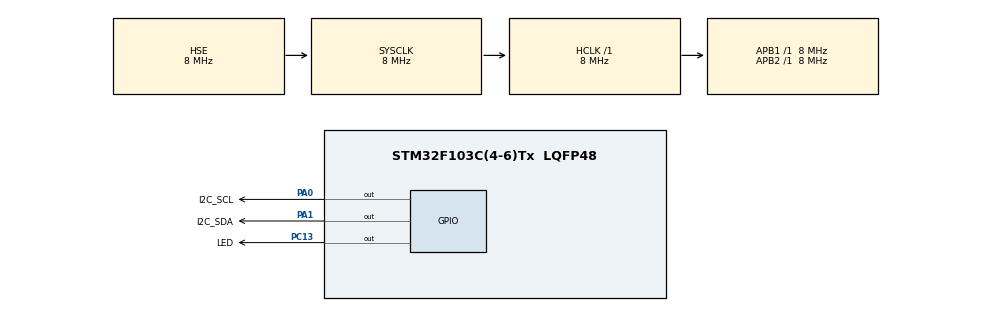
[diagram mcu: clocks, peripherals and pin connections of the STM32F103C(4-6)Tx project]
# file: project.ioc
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Mcu.Family=STM32F1
Mcu.Name=STM32F103C(4-6)Tx
Mcu.Package=LQFP48
NVIC.PriorityGroup=NVIC_PRIORITYGROUP_4
NVIC.TIM3_IRQn=true\:0\:0\:false\:false\:true\:true\:true\:true
PA0-WKUP.GPIO_Label=I2C_SCL
PA0-WKUP.GPIO_ModeDefaultOutputPP=GPIO_MODE_OUTPUT_OD
PA0-WKUP.GPIO_PuPd=GPIO_PULLUP
PA0-WKUP.GPIO_Speed=GPIO_SPEED_FREQ_HIGH
PA0-WKUP.PinState=GPIO_PIN_SET
PA0-WKUP.Signal=GPIO_Output
PA1.GPIO_Label=I2C_SDA
PA1.GPIO_ModeDefaultOutputPP=GPIO_MODE_OUTPUT_OD
PA1.GPIO_PuPd=GPIO_PULLUP
PA1.GPIO_Speed=GPIO_SPEED_FREQ_HIGH
PA1.PinState=GPIO_PIN_SET
PA1.Signal=GPIO_Output
PA13.Mode=Serial_Wire
PA13.Signal=SYS_JTMS-SWDIO
PA14.Mode=Serial_Wire
PA14.Signal=SYS_JTCK-SWCLK
PC13-TAMPER-RTC.GPIO_Label=LED
PC13-TAMPER-RTC.Signal=GPIO_Output
PC14-OSC32_IN.Mode=LSE-External-Oscillator
PC14-OSC32_IN.Signal=RCC_OSC32_IN
PC15-OSC32_OUT.Mode=LSE-External-Oscillator
PC15-OSC32_OUT.Signal=RCC_OSC32_OUT
PD0-OSC_IN.Mode=HSE-External-Oscillator
PD0-OSC_IN.Signal=RCC_OSC_IN
PD1-OSC_OUT.Mode=HSE-External-Oscillator
PD1-OSC_OUT.Signal=RCC_OSC_OUT
ProjectManager.HeapSize=0x200
ProjectManager.StackSize=0x400
ProjectManager.TargetToolchain=MDK-ARM V5.32
RCC.AHBFreq_Value=8000000
RCC.APB1Freq_Value=8000000
RCC.APB1TimFreq_Value=8000000
RCC.APB2Freq_Value=8000000
RCC.APB2TimFreq_Value=8000000
RCC.HCLKFreq_Value=8000000
RCC.SYSCLKFreq_VALUE=8000000
RCC.SYSCLKSource=RCC_SYSCLKSOURCE_HSE
RCC.USBFreq_Value=8000000
TIM3.Period=(250-1)
TIM3.Prescaler=(8000-1)
VP_TIM3_VS_ClockSourceINT.Mode=Internal
board=custom

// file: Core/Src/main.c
/* USER CODE BEGIN Header */
/**
 ******************************************************************************
 * @file           : main.c
 * @brief          : Main program body
 ******************************************************************************
 * @attention
 *
 * Copyright (c) 2023 STMicroelectronics.
 * All rights reserved.
 *
 * This software is licensed under terms that can be found in the LICENSE file
 * in the root directory of this software component.
 * If no LICENSE file comes with this software, it is provided AS-IS.
 *
 ******************************************************************************
 */
/* USER CODE END Header */
#include "main.h"
#include "tim.h"
#include "gpio.h"

/* USER CODE BEGIN Includes */
#include "asp_ssd1306.h"
#include "asp_hmc5883l.h"
/* USER CODE END Includes */

void SystemClock_Config(void);

int main(void)
{

  /* MCU Configuration--------------------------------------------------------*/

  /* Reset of all peripherals, Initializes the Flash interface and the Systick. */
  HAL_Init();

  /* Configure the system clock */
  SystemClock_Config();

  /* Initialize all configured peripherals */
  MX_GPIO_Init();
  MX_TIM3_Init();
  /* USER CODE BEGIN 2 */

  /* 器件延时 */
  HAL_Delay(100);

  /* ssd1306 初始化 */
  asp_ssd1306_init();

  /* hmc5883l初始化 */
  asp_hmc5883l_init();

  HAL_TIM_Base_Start_IT(&htim3);

  /* USER CODE END 2 */

  /* Infinite loop */
  while (1)
  {

    /* USER CODE BEGIN 3 */
    __nop();
  }
  /* USER CODE END 3 */
}

void SystemClock_Config(void)
{
  RCC_OscInitTypeDef RCC_OscInitStruct = {0};
  RCC_ClkInitTypeDef RCC_ClkInitStruct = {0};

  /** Initializes the RCC Oscillators according to the specified parameters
   * in the RCC_OscInitTypeDef structure.
   */
  RCC_OscInitStruct.OscillatorType = RCC_OSCILLATORTYPE_HSE;
  RCC_OscInitStruct.HSEState = RCC_HSE_ON;
  RCC_OscInitStruct.PLL.PLLState = RCC_PLL_NONE;
  if (HAL_RCC_OscConfig(&RCC_OscInitStruct) != HAL_OK)
  {
    Error_Handler();
  }

  /** Initializes the CPU, AHB and APB buses clocks
   */
  RCC_ClkInitStruct.ClockType = RCC_CLOCKTYPE_HCLK | RCC_CLOCKTYPE_SYSCLK | RCC_CLOCKTYPE_PCLK1 | RCC_CLOCKTYPE_PCLK2;
  RCC_ClkInitStruct.SYSCLKSource = RCC_SYSCLKSOURCE_HSE;
  RCC_ClkInitStruct.AHBCLKDivider = RCC_SYSCLK_DIV1;
  RCC_ClkInitStruct.APB1CLKDivider = RCC_HCLK_DIV1;
  RCC_ClkInitStruct.APB2CLKDivider = RCC_HCLK_DIV1;

  if (HAL_RCC_ClockConfig(&RCC_ClkInitStruct, FLASH_LATENCY_0) != HAL_OK)
  {
    Error_Handler();
  }
}

/* USER CODE BEGIN 4 */

char str[10];

char str_direc[8][5] = {" 北 ", "东北", " 东 ", "东南", " 南 ", "西南", " 西 ", "西北"};

void HAL_TIM_PeriodElapsedCallback(TIM_HandleTypeDef *htim)
{
  HAL_GPIO_TogglePin(LED_GPIO_Port, LED_Pin);

  /* 获取方向角度 */
  float direction = asp_hmc5883l_get_direction();

  float a = 22.5;
  float b = 22.5 + 45;

  /* 换算成8个方位 */
  if ((direction <= 22.5) || (direction > (360 - 22.5)))
  {
    ssd1306_display_string(32, 0, str_direc[0]);
  }
  else
  {
    for (int i = 0; i < 7; i++)
    {
      if ((direction > a) && (direction <= b))
      {
        ssd1306_display_string(32, 0, str_direc[i + 1]);

        break;
      }

      a += 45;
      b += 45;
    }
  }

  sprintf(str, "%3.0f", direction);

  ssd1306_display_string(40, 32, str);
}

void asp_count_down_cb(int count)
{
  static int i;

  if (count >= i)
  {
    sprintf(str, "%2d", 10 - i);

    ssd1306_display_string(40, 16, str);

    i++;
  }
}

/* USER CODE END 4 */

void Error_Handler(void)
{
  __disable_irq();
  while (1)
  {
  }
}
